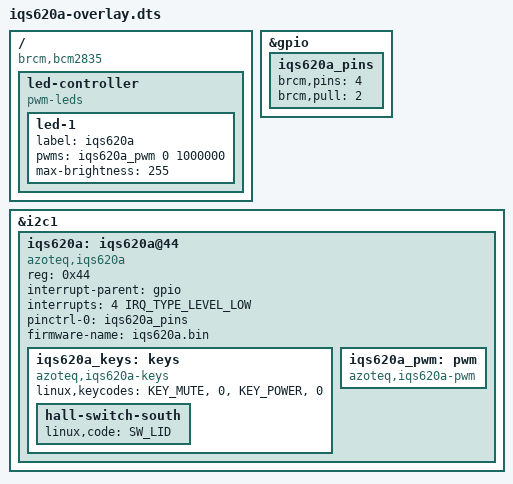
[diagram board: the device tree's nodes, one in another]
// SPDX-License-Identifier: GPL-2.0-or-later
// Definitions for Azoteq IQS620A multi-function sensor
/dts-v1/;
/plugin/;
#include <dt-bindings/input/input.h>
#include <dt-bindings/interrupt-controller/irq.h>

/ {
	compatible = "brcm,bcm2835";

	fragment@0 {
		target = <&gpio>;
		__overlay__ {
			iqs620a_pins: iqs620a_pins {
				brcm,pins = <4>;
				brcm,pull = <2>;
			};
		};
	};

	fragment@1 {
		target = <&i2c1>;
		__overlay__ {
			#address-cells = <1>;
			#size-cells = <0>;
			status = "okay";

			iqs620a: iqs620a@44 {
				compatible = "azoteq,iqs620a";
				reg = <0x44>;
				interrupt-parent = <&gpio>;
				interrupts = <4 IRQ_TYPE_LEVEL_LOW>;
				pinctrl-names = "default";
				pinctrl-0 = <&iqs620a_pins>;
				firmware-name = "iqs620a.bin";

				iqs620a_keys: keys {
					compatible = "azoteq,iqs620a-keys";
					linux,keycodes = <KEY_MUTE>,
							 <0>,
							 <KEY_POWER>,
							 <0>;

					hall-switch-south {
						linux,code = <SW_LID>;
					};
				};

				iqs620a_pwm: pwm {
					compatible = "azoteq,iqs620a-pwm";
					#pwm-cells = <2>;
				};
			};
		};
	};

	fragment@2 {
		target-path = "/";
		__overlay__ {
			led-controller {
				compatible = "pwm-leds";

				led-1 {
					label = "iqs620a";
					pwms = <&iqs620a_pwm 0 1000000>;
					max-brightness = <255>;
				};
			};
		};
	};

	__overrides__ {
		interrupt = <&iqs620a_pins>,"brcm,pins:0",
			    <&iqs620a>,"interrupts:0";
		config = <&iqs620a>,"firmware-name";
	};
};
